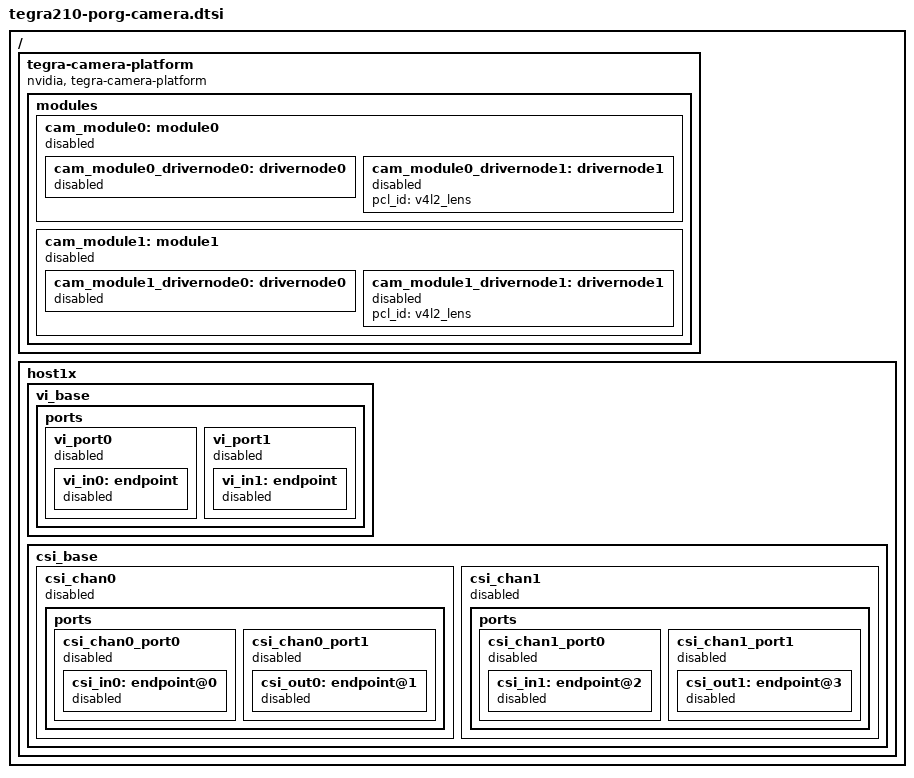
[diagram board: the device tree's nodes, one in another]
/*
 * Copyright (c) 2018-2019, NVIDIA CORPORATION.  All rights reserved.
 *
 * This program is free software; you can redistribute it and/or modify
 * it under the terms of the GNU General Public License as published by
 * the Free Software Foundation; either version 2 of the License, or
 * (at your option) any later version.
 *
 * This program is distributed in the hope that it will be useful, but WITHOUT
 * ANY WARRANTY; without even the implied warranty of MERCHANTABILITY or
 * FITNESS FOR A PARTICULAR PURPOSE.  See the GNU General Public License for
 * more details.
 *
 * You should have received a copy of the GNU General Public License
 * along with this program.  If not, see <http://www.gnu.org/licenses/>.
 */
#include "tegra210-porg-camera-rbpcv2-dual-imx219.dtsi"
#include "tegra210-porg-camera-rbpcv2-imx219.dtsi"

/ {
	tegra-camera-platform {
		compatible = "nvidia, tegra-camera-platform";

		modules {
			cam_module0: module0 {
				status = "disabled";
				cam_module0_drivernode0: drivernode0 {
					status = "disabled";
				};
				cam_module0_drivernode1: drivernode1 {
					status = "disabled";
					pcl_id = "v4l2_lens";
				};
			};
			cam_module1: module1 {
				status = "disabled";
				cam_module1_drivernode0: drivernode0 {
					status = "disabled";
				};
				cam_module1_drivernode1: drivernode1 {
					status = "disabled";
					pcl_id = "v4l2_lens";
				};
			};
		};
	};

	/* all vi and csi ports are disabled by default */
	host1x {
		vi_base {
			ports {
				vi_port0 {
					status = "disabled";
					vi_in0: endpoint {
						status = "disabled";
					};
				};
				vi_port1 {
					status = "disabled";
					vi_in1: endpoint {
						status = "disabled";
					};
				};
			};
		};
		csi_base{
			csi_chan0 {
				status = "disabled";
				ports {
					csi_chan0_port0 {
						status = "disabled";
						csi_in0: endpoint@0 {
							status = "disabled";
						};
					};
					csi_chan0_port1 {
						status = "disabled";
						csi_out0: endpoint@1 {
							status = "disabled";
						};
					};
				};
			};
			csi_chan1 {
				status = "disabled";
				ports {
					csi_chan1_port0 {
						status = "disabled";
						csi_in1: endpoint@2 {
							status = "disabled";
						};
					};
					csi_chan1_port1 {
						status = "disabled";
						csi_out1: endpoint@3 {
							status = "disabled";
						};
					};
				};
			};
		};
	};

};
